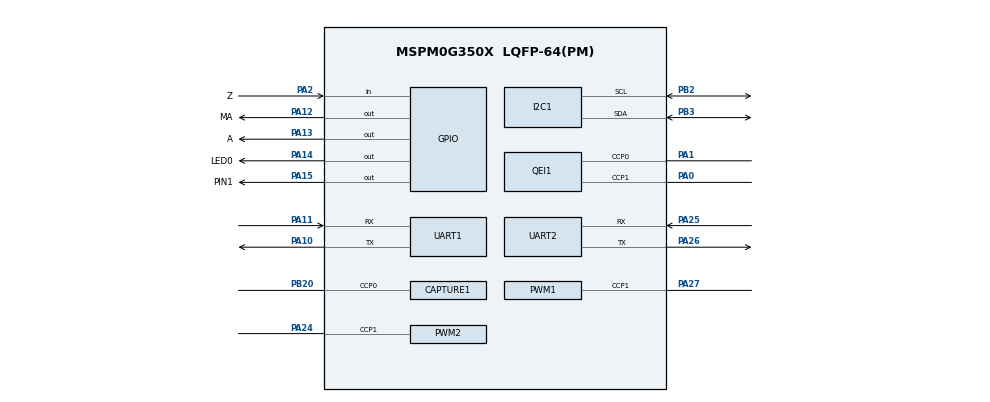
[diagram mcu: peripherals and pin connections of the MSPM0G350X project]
/**
 * @cliArgs --device "MSPM0G350X" --part "Default" --package "LQFP-64(PM)" --product "mspm0_sdk@2.11.00.07"
 * @versions {"tool":"1.27.0+4565"}
 */

/**
 * Import the modules used in this configuration.
 */
const ADC12    = scripting.addModule("/ti/driverlib/ADC12", {}, false);
const ADC121   = ADC12.addInstance();
const CAPTURE  = scripting.addModule("/ti/driverlib/CAPTURE", {}, false);
const CAPTURE1 = CAPTURE.addInstance();
const GPIO     = scripting.addModule("/ti/driverlib/GPIO", {}, false);
const GPIO1    = GPIO.addInstance();
const GPIO3    = GPIO.addInstance();
const GPIO4    = GPIO.addInstance();
const GPIO5    = GPIO.addInstance();
const GPIO6    = GPIO.addInstance();
const I2C      = scripting.addModule("/ti/driverlib/I2C", {}, false);
const I2C1     = I2C.addInstance();
const PWM      = scripting.addModule("/ti/driverlib/PWM", {}, false);
const PWM1     = PWM.addInstance();
const PWM2     = PWM.addInstance();
const QEI      = scripting.addModule("/ti/driverlib/QEI", {}, false);
const QEI1     = QEI.addInstance();
const SYSCTL   = scripting.addModule("/ti/driverlib/SYSCTL");
const SYSTICK  = scripting.addModule("/ti/driverlib/SYSTICK");
const TIMER    = scripting.addModule("/ti/driverlib/TIMER", {}, false);
const TIMER1   = TIMER.addInstance();
const TIMER2   = TIMER.addInstance();
const UART     = scripting.addModule("/ti/driverlib/UART", {}, false);
const UART1    = UART.addInstance();
const UART2    = UART.addInstance();
const VREF     = scripting.addModule("/ti/driverlib/VREF");

/**
 * Write custom configuration values to the imported modules.
 */
const divider9       = system.clockTree["UDIV"];
divider9.divideValue = 2;

const multiplier2         = system.clockTree["PLL_QDIV"];
multiplier2.multiplyValue = 5;

const mux4       = system.clockTree["EXHFMUX"];
mux4.inputSelect = "EXHFMUX_XTAL";

const mux8       = system.clockTree["HSCLKMUX"];
mux8.inputSelect = "HSCLKMUX_SYSPLL0";

const pinFunction4     = system.clockTree["HFXT"];
pinFunction4.inputFreq = 40;
pinFunction4.enable    = true;

ADC121.$name                      = "xuanniu";
ADC121.adcMem0vref                = "VREF";
ADC121.adcMem0chansel             = "DL_ADC12_INPUT_CHAN_1";
ADC121.repeatMode                 = true;
ADC121.peripheral.adcPin1.$assign = "PA16";
ADC121.adcPin1Config.$name        = "ti_driverlib_gpio_GPIOPinGeneric4";

const Board = scripting.addModule("/ti/driverlib/Board", {}, false);

CAPTURE1.$name                              = "ENCODER_PWM";
CAPTURE1.timerPeriod                        = "50.0ms";
CAPTURE1.timerStartTimer                    = true;
CAPTURE1.captMode                           = "COMBINED";
CAPTURE1.peripheral.$assign                 = "TIMG12";
CAPTURE1.peripheral.ccp0Pin.$assign         = "PB20";
CAPTURE1.ccp0PinConfig.hideOutputInversion  = scripting.forceWrite(false);
CAPTURE1.ccp0PinConfig.onlyInternalResistor = scripting.forceWrite(false);
CAPTURE1.ccp0PinConfig.passedPeripheralType = scripting.forceWrite("Digital");
CAPTURE1.ccp0PinConfig.$name                = "ti_driverlib_gpio_GPIOPinGeneric6";

GPIO1.$name                         = "LED";
GPIO1.associatedPins[0].$name       = "LED0";
GPIO1.associatedPins[0].pin.$assign = "PA14";

GPIO3.$name                          = "BEEP";
GPIO3.associatedPins[0].$name        = "PIN1";
GPIO3.associatedPins[0].initialValue = "SET";
GPIO3.associatedPins[0].pin.$assign  = "PA15";

GPIO4.$name                          = "DIR";
GPIO4.associatedPins[0].$name        = "A";
GPIO4.associatedPins[0].assignedPort = "PORTA";
GPIO4.associatedPins[0].pin.$assign  = "PA13";

GPIO5.$name                         = "EN";
GPIO5.associatedPins[0].$name       = "MA";
GPIO5.associatedPins[0].pin.$assign = "PA12";

GPIO6.$name                         = "ENCODER_Z";
GPIO6.associatedPins[0].$name       = "Z";
GPIO6.associatedPins[0].direction   = "INPUT";
GPIO6.associatedPins[0].pin.$assign = "PA2";

I2C1.$name                             = "OLED";
I2C1.basicEnableController             = true;
I2C1.advDigitalGlitchFilter            = "CLOCKS_1";
I2C1.advControllerRXFIFOTRIG           = "BYTES_8";
I2C1.advControllerTXFIFOTRIG           = "BYTES_7";
I2C1.enableDMAEvent1                   = false;
I2C1.enableDMAEvent2                   = false;
I2C1.peripheral.$assign                = "I2C1";
I2C1.peripheral.sdaPin.$assign         = "PB3";
I2C1.peripheral.sclPin.$assign         = "PB2";
I2C1.sdaPinConfig.hideOutputInversion  = scripting.forceWrite(false);
I2C1.sdaPinConfig.onlyInternalResistor = scripting.forceWrite(false);
I2C1.sdaPinConfig.passedPeripheralType = scripting.forceWrite("Digital");
I2C1.sdaPinConfig.$name                = "ti_driverlib_gpio_GPIOPinGeneric0";
I2C1.sdaPinConfig.enableConfig         = true;
I2C1.sdaPinConfig.internalResistor     = "PULL_UP";
I2C1.sclPinConfig.hideOutputInversion  = scripting.forceWrite(false);
I2C1.sclPinConfig.onlyInternalResistor = scripting.forceWrite(false);
I2C1.sclPinConfig.passedPeripheralType = scripting.forceWrite("Digital");
I2C1.sclPinConfig.$name                = "ti_driverlib_gpio_GPIOPinGeneric1";
I2C1.sclPinConfig.enableConfig         = true;
I2C1.sclPinConfig.internalResistor     = "PULL_UP";

PWM1.$name                              = "PWM_SERVO";
PWM1.ccIndex                            = [1];
PWM1.clockDivider                       = 8;
PWM1.clockPrescale                      = 10;
PWM1.timerCount                         = 20000;
PWM1.ccp1PinConfig.direction            = scripting.forceWrite("OUTPUT");
PWM1.ccp1PinConfig.hideOutputInversion  = scripting.forceWrite(false);
PWM1.ccp1PinConfig.onlyInternalResistor = scripting.forceWrite(false);
PWM1.ccp1PinConfig.passedPeripheralType = scripting.forceWrite("Digital");
PWM1.ccp1PinConfig.$name                = "ti_driverlib_gpio_GPIOPinGeneric10";
PWM1.peripheral.$assign                 = "TIMG7";
PWM1.peripheral.ccp1Pin.$assign         = "PA27";
PWM1.PWM_CHANNEL_1.$name                = "ti_driverlib_pwm_PWMTimerCC0";

PWM2.$name                              = "PWM_0";
PWM2.ccIndex                            = [1];
PWM2.clockPrescale                      = 80;
PWM2.ccp1PinConfig.direction            = scripting.forceWrite("OUTPUT");
PWM2.ccp1PinConfig.hideOutputInversion  = scripting.forceWrite(false);
PWM2.ccp1PinConfig.onlyInternalResistor = scripting.forceWrite(false);
PWM2.ccp1PinConfig.passedPeripheralType = scripting.forceWrite("Digital");
PWM2.ccp1PinConfig.$name                = "ti_driverlib_gpio_GPIOPinGeneric9";
PWM2.peripheral.$assign                 = "TIMA1";
PWM2.peripheral.ccp1Pin.$assign         = "PA24";
PWM2.PWM_CHANNEL_1.$name                = "ti_driverlib_pwm_PWMTimerCC1";

QEI1.$name                      = "QEI_0";
QEI1.timerStartTimer            = true;
QEI1.peripheral.$assign         = "TIMG8";
QEI1.peripheral.ccp0Pin.$assign = "PA1";
QEI1.peripheral.ccp1Pin.$assign = "PA0";
QEI1.ccp0PinConfig.$name        = "ti_driverlib_gpio_GPIOPinGeneric8";
QEI1.ccp1PinConfig.$name        = "ti_driverlib_gpio_GPIOPinGeneric11";

SYSCTL.forceDefaultClkConfig = true;
SYSCTL.clockTreeEn           = true;

SYSTICK.periodEnable    = true;
SYSTICK.period          = 80000;
SYSTICK.interruptEnable = true;
SYSTICK.systickEnable   = true;

TIMER1.$name              = "US_TIMER";
TIMER1.timerClkDiv        = 8;
TIMER1.timerClkPrescale   = 10;
TIMER1.timerMode          = "ONE_SHOT_UP";
TIMER1.timerStartTimer    = true;
TIMER1.peripheral.$assign = "TIMG6";

TIMER2.$name              = "TIMER_0";
TIMER2.timerClkPrescale   = 32;
TIMER2.timerStartTimer    = true;
TIMER2.timerMode          = "PERIODIC";
TIMER2.timerPeriod        = "5 ms";
TIMER2.peripheral.$assign = "TIMG0";

UART1.$name                            = "DEBUG";
UART1.targetBaudRate                   = 115200;
UART1.enabledInterrupts                = ["RX"];
UART1.peripheral.$assign               = "UART0";
UART1.peripheral.rxPin.$assign         = "PA11";
UART1.peripheral.txPin.$assign         = "PA10";
UART1.txPinConfig.direction            = scripting.forceWrite("OUTPUT");
UART1.txPinConfig.hideOutputInversion  = scripting.forceWrite(false);
UART1.txPinConfig.onlyInternalResistor = scripting.forceWrite(false);
UART1.txPinConfig.passedPeripheralType = scripting.forceWrite("Digital");
UART1.txPinConfig.$name                = "ti_driverlib_gpio_GPIOPinGeneric2";
UART1.rxPinConfig.hideOutputInversion  = scripting.forceWrite(false);
UART1.rxPinConfig.onlyInternalResistor = scripting.forceWrite(false);
UART1.rxPinConfig.passedPeripheralType = scripting.forceWrite("Digital");
UART1.rxPinConfig.$name                = "ti_driverlib_gpio_GPIOPinGeneric3";

UART2.$name                            = "K230_UART";
UART2.targetBaudRate                   = 115200;
UART2.peripheral.$assign               = "UART3";
UART2.peripheral.rxPin.$assign         = "PA25";
UART2.peripheral.txPin.$assign         = "PA26";
UART2.txPinConfig.direction            = scripting.forceWrite("OUTPUT");
UART2.txPinConfig.hideOutputInversion  = scripting.forceWrite(false);
UART2.txPinConfig.onlyInternalResistor = scripting.forceWrite(false);
UART2.txPinConfig.passedPeripheralType = scripting.forceWrite("Digital");
UART2.txPinConfig.$name                = "ti_driverlib_gpio_GPIOPinGeneric7";
UART2.rxPinConfig.hideOutputInversion  = scripting.forceWrite(false);
UART2.rxPinConfig.onlyInternalResistor = scripting.forceWrite(false);
UART2.rxPinConfig.passedPeripheralType = scripting.forceWrite("Digital");
UART2.rxPinConfig.$name                = "ti_driverlib_gpio_GPIOPinGeneric14";

VREF.basicIntVolt           = "DL_VREF_BUFCONFIG_OUTPUT_2_5V";
VREF.profile                = "INT_2_5_V";
VREF.vrefPosPinConfig.$name = "ti_driverlib_gpio_GPIOPinGeneric5";

/**
 * Pinmux solution for unlocked pins/peripherals. This ensures that minor changes to the automatic solver in a future
 * version of the tool will not impact the pinmux you originally saw.  These lines can be completely deleted in order to
 * re-solve from scratch.
 */
pinFunction4.peripheral.$suggestSolution           = "SYSCTL";
pinFunction4.peripheral.hfxInPin.$suggestSolution  = "PA5";
pinFunction4.peripheral.hfxOutPin.$suggestSolution = "PA6";
ADC121.peripheral.$suggestSolution                 = "ADC1";
Board.peripheral.$suggestSolution                  = "DEBUGSS";
Board.peripheral.swclkPin.$suggestSolution         = "PA20";
Board.peripheral.swdioPin.$suggestSolution         = "PA19";
VREF.peripheral.$suggestSolution                   = "VREF";
VREF.peripheral.vrefPosPin.$suggestSolution        = "PA23";
